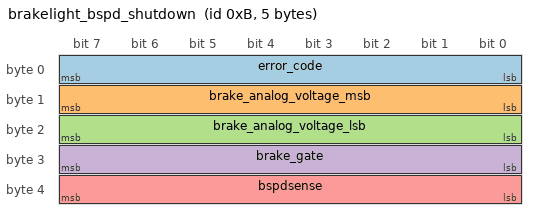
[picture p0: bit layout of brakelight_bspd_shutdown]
BO_ 11 brakelight_bspd_shutdown: 5 brakelight_bspd_shutdown
 SG_ error_code : 7|8@0+ (1,0) [0|1] "" Vector_XXX
 SG_ brake_analog_voltage_msb : 15|8@0+ (1,0) [0|1] "" Vector_XXX
 SG_ brake_analog_voltage_lsb : 23|8@0+ (1,0) [0|1] "" Vector_XXX
 SG_ brake_gate : 31|8@0+ (1,0) [0|1] "" Vector_XXX
 SG_ bspdsense : 39|8@0+ (1,0) [0|1] "" Vector_XXX
